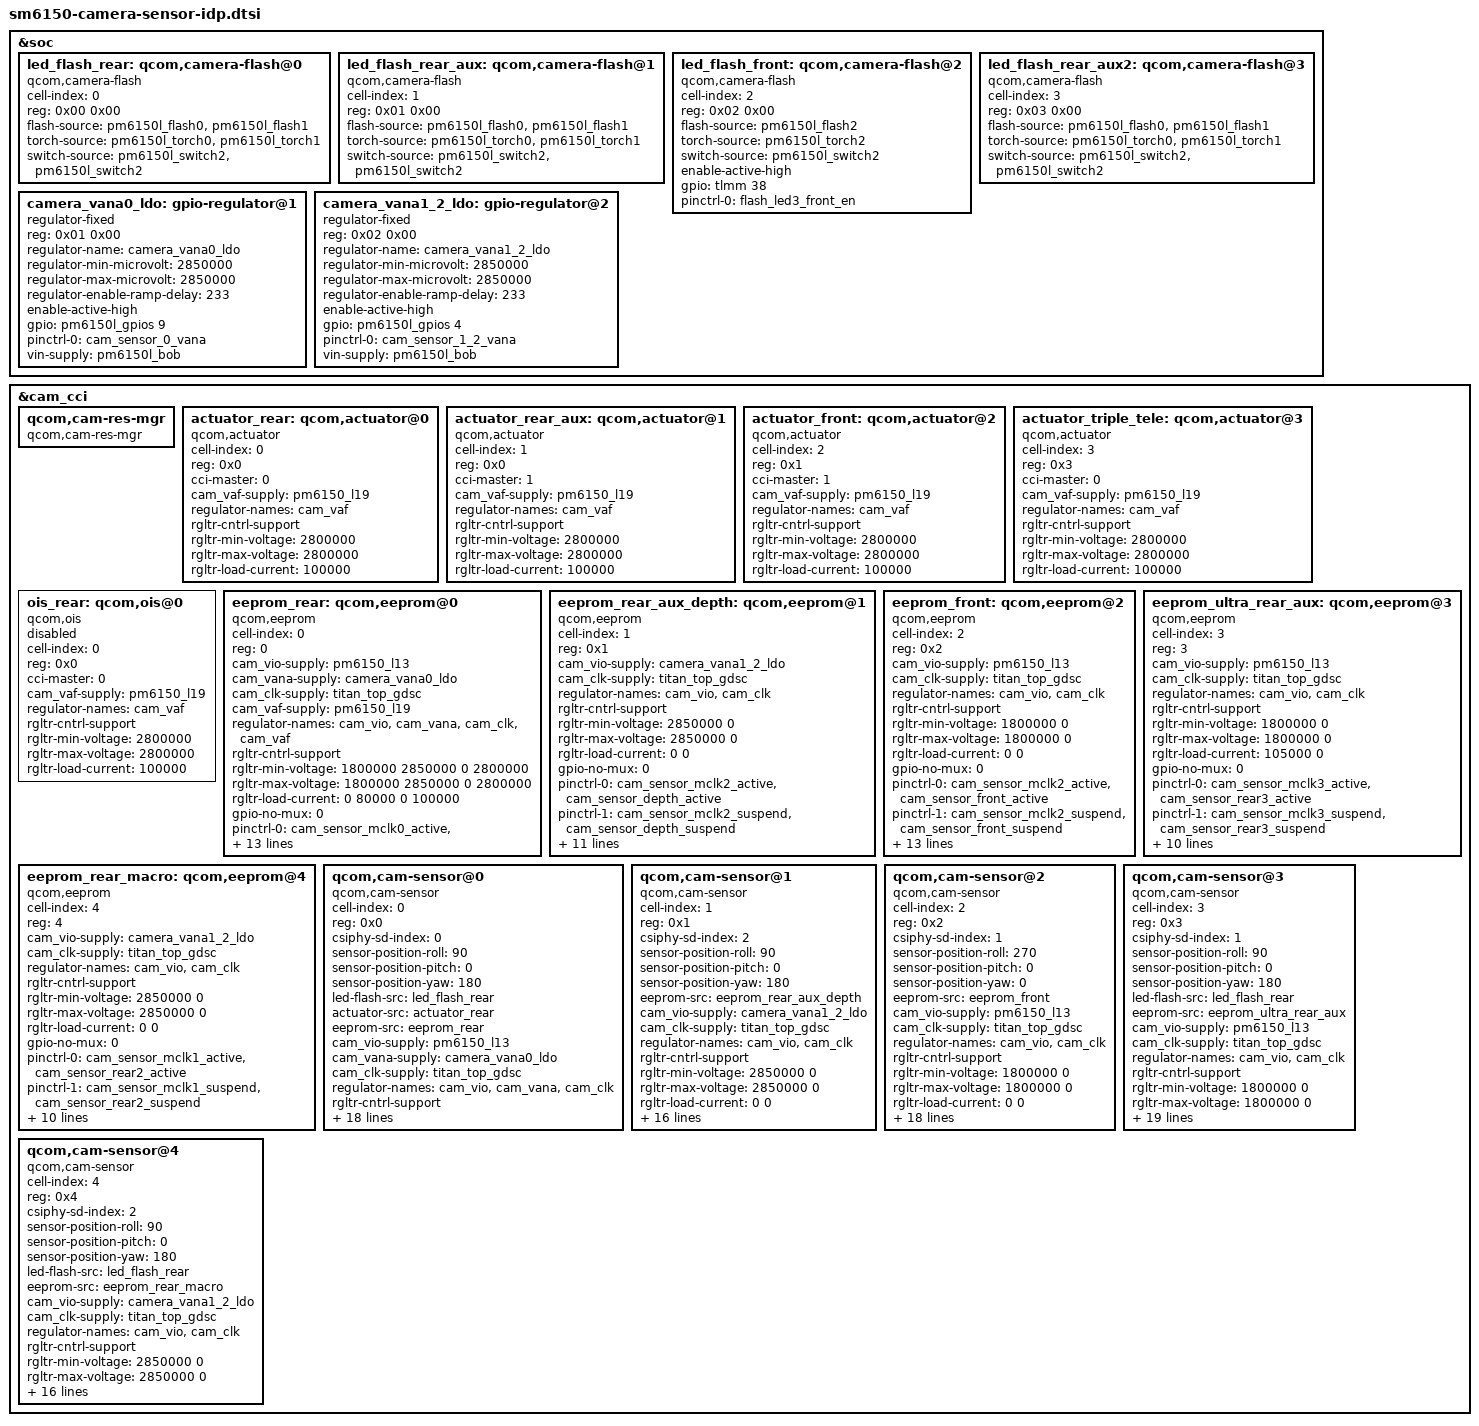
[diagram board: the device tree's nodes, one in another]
/*
 * Copyright (c) 2018-2019, The Linux Foundation. All rights reserved.
 * Copyright (C) 2021 XiaoMi, Inc.
 *
 * This program is free software; you can redistribute it and/or modify
 * it under the terms of the GNU General Public License version 2 and
 * only version 2 as published by the Free Software Foundation.
 *
 * This program is distributed in the hope that it will be useful,
 * but WITHOUT ANY WARRANTY; without even the implied warranty of
 * MERCHANTABILITY or FITNESS FOR A PARTICULAR PURPOSE.  See the
 * GNU General Public License for more details.
 */

&soc {

	led_flash_rear: qcom,camera-flash@0 {
		cell-index = <0>;
		reg = <0x00 0x00>;
		compatible = "qcom,camera-flash";
		flash-source = <&pm6150l_flash0 &pm6150l_flash1>;
		torch-source = <&pm6150l_torch0 &pm6150l_torch1>;
		switch-source = <&pm6150l_switch2 &pm6150l_switch2>;
		status = "ok";
	};

	led_flash_rear_aux: qcom,camera-flash@1 {
		cell-index = <1>;
		reg = <0x01 0x00>;
		compatible = "qcom,camera-flash";
		flash-source = <&pm6150l_flash0 &pm6150l_flash1>;
		torch-source = <&pm6150l_torch0 &pm6150l_torch1>;
		switch-source = <&pm6150l_switch2 &pm6150l_switch2>;
		status = "ok";
	};

	led_flash_front: qcom,camera-flash@2 {
		cell-index = <2>;
		reg = <0x02 0x00>;
		compatible = "qcom,camera-flash";
		flash-source = <&pm6150l_flash2>;
		torch-source = <&pm6150l_torch2>;
		switch-source = <&pm6150l_switch2>;
		status = "ok";
		enable-active-high;
		gpio = <&tlmm 38 0>;
		pinctrl-names = "default";
		pinctrl-0 = <&flash_led3_front_en>;
	};

	led_flash_rear_aux2: qcom,camera-flash@3 {
		cell-index = <3>;
		reg = <0x03 0x00>;
		compatible = "qcom,camera-flash";
		flash-source = <&pm6150l_flash0 &pm6150l_flash1>;
		torch-source = <&pm6150l_torch0 &pm6150l_torch1>;
		switch-source = <&pm6150l_switch2 &pm6150l_switch2>;
		status = "ok";
	};

	camera_vana0_ldo: gpio-regulator@1 {
		compatible = "regulator-fixed";
		reg = <0x01 0x00>;
		regulator-name = "camera_vana0_ldo";
		regulator-min-microvolt = <2850000>;
		regulator-max-microvolt = <2850000>;
		regulator-enable-ramp-delay = <233>;
		enable-active-high;
		gpio = <&pm6150l_gpios 9 0>;
		pinctrl-names = "default";
		pinctrl-0 = <&cam_sensor_0_vana>;
		vin-supply = <&pm6150l_bob>;
	};

	camera_vana1_2_ldo: gpio-regulator@2 {
		compatible = "regulator-fixed";
		reg = <0x02 0x00>;
		regulator-name = "camera_vana1_2_ldo";
		regulator-min-microvolt = <2850000>;
		regulator-max-microvolt = <2850000>;
		regulator-enable-ramp-delay = <233>;
		enable-active-high;
		gpio = <&pm6150l_gpios 4 0>;
		pinctrl-names = "default";
		pinctrl-0 = <&cam_sensor_1_2_vana>;
		vin-supply = <&pm6150l_bob>;
	};
};

&cam_cci {
	qcom,cam-res-mgr {
		compatible = "qcom,cam-res-mgr";
		status = "ok";
	};

	actuator_rear: qcom,actuator@0 {
		cell-index = <0>;
		reg = <0x0>;
		compatible = "qcom,actuator";
		cci-master = <0>;
		cam_vaf-supply = <&pm6150_l19>;
		regulator-names = "cam_vaf";
		rgltr-cntrl-support;
		rgltr-min-voltage = <2800000>;
		rgltr-max-voltage = <2800000>;
		rgltr-load-current = <100000>;
	};

	actuator_rear_aux: qcom,actuator@1 {
		cell-index = <1>;
		reg = <0x0>;
		compatible = "qcom,actuator";
		cci-master = <1>;
		cam_vaf-supply = <&pm6150_l19>;
		regulator-names = "cam_vaf";
		rgltr-cntrl-support;
		rgltr-min-voltage = <2800000>;
		rgltr-max-voltage = <2800000>;
		rgltr-load-current = <100000>;
	};

	actuator_front: qcom,actuator@2 {
		cell-index = <2>;
		reg = <0x1>;
		compatible = "qcom,actuator";
		cci-master = <1>;
		cam_vaf-supply = <&pm6150_l19>;
		regulator-names = "cam_vaf";
		rgltr-cntrl-support;
		rgltr-min-voltage = <2800000>;
		rgltr-max-voltage = <2800000>;
		rgltr-load-current = <100000>;
	};

	actuator_triple_tele: qcom,actuator@3 {
		cell-index = <3>;
		reg = <0x3>;
		compatible = "qcom,actuator";
		cci-master = <0>;
		cam_vaf-supply = <&pm6150_l19>;
		regulator-names = "cam_vaf";
		rgltr-cntrl-support;
		rgltr-min-voltage = <2800000>;
		rgltr-max-voltage = <2800000>;
		rgltr-load-current = <100000>;
	};

	ois_rear: qcom,ois@0 {
		cell-index = <0>;
		reg = <0x0>;
		compatible = "qcom,ois";
		cci-master = <0>;
		cam_vaf-supply = <&pm6150_l19>;
		regulator-names = "cam_vaf";
		rgltr-cntrl-support;
		rgltr-min-voltage = <2800000>;
		rgltr-max-voltage = <2800000>;
		rgltr-load-current = <100000>;
		status = "disabled";
	};

	eeprom_rear: qcom,eeprom@0 {
		cell-index = <0>;
		reg = <0>;
		compatible = "qcom,eeprom";
		cam_vio-supply = <&pm6150_l13>;
		cam_vana-supply = <&camera_vana0_ldo>;
		cam_clk-supply = <&titan_top_gdsc>;
		cam_vaf-supply = <&pm6150_l19>;
		regulator-names = "cam_vio", "cam_vana",
			"cam_clk", "cam_vaf";
		rgltr-cntrl-support;
		rgltr-min-voltage = <1800000 2850000 0 2800000>;
		rgltr-max-voltage = <1800000 2850000 0 2800000>;
		rgltr-load-current = <0 80000 0 100000>;
		gpio-no-mux = <0>;
		pinctrl-names = "cam_default", "cam_suspend";
		pinctrl-0 = <&cam_sensor_mclk0_active
				&cam_sensor_rear_active>;
		pinctrl-1 = <&cam_sensor_mclk0_suspend
				&cam_sensor_rear_suspend>;
		gpios = <&tlmm 28 0>,
			<&tlmm 47 0>;
		gpio-reset = <1>;
		gpio-req-tbl-num = <0 1>;
		gpio-req-tbl-flags = <1 0>;
		gpio-req-tbl-label = "CAMIF_MCLK0",
					"CAM_RESET0";
		sensor-mode = <0>;
		cci-master = <0>;
		status = "ok";
		clocks = <&clock_camcc CAM_CC_MCLK0_CLK>;
		clock-names = "cam_clk";
		clock-cntl-level = "turbo";
		clock-rates = <19200000>;
	};

	eeprom_rear_aux_depth: qcom,eeprom@1 {
		cell-index = <1>;
		reg = <0x1>;
		compatible = "qcom,eeprom";
		cam_vio-supply = <&camera_vana1_2_ldo>;
		cam_clk-supply = <&titan_top_gdsc>;
		regulator-names = "cam_vio",
			"cam_clk";
		rgltr-cntrl-support;
		rgltr-min-voltage = <2850000 0>;
		rgltr-max-voltage = <2850000 0>;
		rgltr-load-current = <0 0>;
		gpio-no-mux = <0>;
		pinctrl-names = "cam_default", "cam_suspend";
		pinctrl-0 = <&cam_sensor_mclk2_active
				&cam_sensor_depth_active>;
		pinctrl-1 = <&cam_sensor_mclk2_suspend
				&cam_sensor_depth_suspend>;
		gpios = <&tlmm 30 0>,
			<&tlmm 37 0>;
		gpio-reset = <1>;
		gpio-req-tbl-num = <0 1>;
		gpio-req-tbl-flags = <1 0>;
		gpio-req-tbl-label = "CAMIF_MCLK2",
					"CAM_RESET_DEPTH";
		sensor-mode = <0>;
		cci-master = <1>;
		status = "ok";
		clocks = <&clock_camcc CAM_CC_MCLK2_CLK>;
		clock-names = "cam_clk";
		clock-cntl-level = "turbo";
		clock-rates = <19200000>;
	};

	eeprom_front: qcom,eeprom@2 {
		cell-index = <2>;
		reg = <0x2>;
		compatible = "qcom,eeprom";
		cam_vio-supply = <&pm6150_l13>;
		//cam_vdig-supply = <&camera_dvdd_ldo>;//dvdd
		cam_clk-supply = <&titan_top_gdsc>;
		regulator-names = "cam_vio", //"cam_vana",
			"cam_clk";
		rgltr-cntrl-support;
		rgltr-min-voltage = <1800000 0>;
		rgltr-max-voltage = <1800000 0>;
		rgltr-load-current = <0 0>;
		gpio-no-mux = <0>;
		pinctrl-names = "cam_default", "cam_suspend";
		pinctrl-0 = <&cam_sensor_mclk2_active
				&cam_sensor_front_active>;
		pinctrl-1 = <&cam_sensor_mclk2_suspend
				&cam_sensor_front_suspend>;
		gpios = <&tlmm 30 0>,
			<&tlmm 38 0>,
		<&tlmm 94 0>,
		<&tlmm 121 0>;
		gpio-reset = <1>;
		gpio-custom1 = <2>;
		gpio-custom2 = <3>;
		gpio-req-tbl-num = <0 1 2 3>;
		gpio-req-tbl-flags = <1 0 0 0>;
		gpio-req-tbl-label = "CAMIF_MCLK2",
					"CAM2_RST_N",
		"CAM_SEL1_8V",
		"CAM_OE_LOW";
		sensor-mode = <0>;
		cci-master = <1>;
		status = "ok";
		clocks = <&clock_camcc CAM_CC_MCLK2_CLK>;
		clock-names = "cam_clk";
		clock-cntl-level = "turbo";
		clock-rates = <19200000>;
	};

	eeprom_ultra_rear_aux: qcom,eeprom@3 {
		cell-index = <3>;
		reg = <3>;
		compatible = "qcom,eeprom";
		cam_vio-supply = <&pm6150_l13>;
		//cam_vana-supply = <&camera_vana0_ldo>;
		cam_clk-supply = <&titan_top_gdsc>;
		regulator-names = "cam_vio",
			"cam_clk";
		rgltr-cntrl-support;
		rgltr-min-voltage = <1800000 0>;
		rgltr-max-voltage = <1800000 0>;
		rgltr-load-current = <105000 0>;
		gpio-no-mux = <0>;
		pinctrl-names = "cam_default", "cam_suspend";
		pinctrl-0 = <&cam_sensor_mclk3_active
				&cam_sensor_rear3_active>;
		pinctrl-1 = <&cam_sensor_mclk3_suspend
				&cam_sensor_rear3_suspend>;
		gpios = <&tlmm 31 0>,
			<&tlmm 40 0>;
		gpio-reset = <1>;
		gpio-req-tbl-num = <0 1>;
		gpio-req-tbl-flags = <1 0>;
		gpio-req-tbl-label = "CAMIF_MCLK3",
					"CAM_RESET3";
		sensor-mode = <0>;
		cci-master = <1>;
		status = "ok";
		clocks = <&clock_camcc CAM_CC_MCLK3_CLK>;
		clock-names = "cam_clk";
		clock-cntl-level = "turbo";
		clock-rates = <19200000>;
	};

	eeprom_rear_macro: qcom,eeprom@4 {
		cell-index = <4>;
		reg = <4>;
		compatible = "qcom,eeprom";
		cam_vio-supply = <&camera_vana1_2_ldo>;
		cam_clk-supply = <&titan_top_gdsc>;
		regulator-names = "cam_vio",
			"cam_clk";
		rgltr-cntrl-support;
		rgltr-min-voltage = <2850000 0>;
		rgltr-max-voltage = <2850000 0>;
		rgltr-load-current = <0 0>;
		gpio-no-mux = <0>;
		pinctrl-names = "cam_default", "cam_suspend";
		pinctrl-0 = <&cam_sensor_mclk1_active
				&cam_sensor_rear2_active>;
		pinctrl-1 = <&cam_sensor_mclk1_suspend
				&cam_sensor_rear2_suspend>;
		gpios = <&tlmm 29 0>,
			<&tlmm 45 0>;
		gpio-reset = <1>;
		gpio-req-tbl-num = <0 1>;
		gpio-req-tbl-flags = <1 0>;
		gpio-req-tbl-label = "CAMIF_MCLK1",
					"CAM_RESET2";
		sensor-mode = <0>;
		cci-master = <0>;
		status = "ok";
		clocks = <&clock_camcc CAM_CC_MCLK1_CLK>;
		clock-names = "cam_clk";
		clock-cntl-level = "turbo";
		clock-rates = <19200000>;
	};

	qcom,cam-sensor@0 {
		cell-index = <0>;
		compatible = "qcom,cam-sensor";
		reg = <0x0>;
		csiphy-sd-index = <0>;
		sensor-position-roll = <90>;
		sensor-position-pitch = <0>;
		sensor-position-yaw = <180>;
		led-flash-src = <&led_flash_rear>;
		actuator-src = <&actuator_rear>;
		//ois-src = <&ois_rear>;
		eeprom-src = <&eeprom_rear>;
		cam_vio-supply = <&pm6150_l13>;
		cam_vana-supply = <&camera_vana0_ldo>;
		cam_clk-supply = <&titan_top_gdsc>;
		regulator-names = "cam_vio", "cam_vana",
			"cam_clk";
		rgltr-cntrl-support;
		rgltr-min-voltage = <1800000 2850000 0>;
		rgltr-max-voltage = <1800000 2850000 0>;
		rgltr-load-current = <0 80000 0>;
		gpio-no-mux = <0>;
		pinctrl-names = "cam_default", "cam_suspend";
		pinctrl-0 = <&cam_sensor_mclk0_active
				&cam_sensor_rear_active>;
		pinctrl-1 = <&cam_sensor_mclk0_suspend
				&cam_sensor_rear_suspend>;
		gpios = <&tlmm 28 0>,
			<&tlmm 47 0>;
		gpio-reset = <1>;
		gpio-req-tbl-num = <0 1>;
		gpio-req-tbl-flags = <1 0>;
		gpio-req-tbl-label = "CAMIF_MCLK0",
					"CAM_RESET0";
		sensor-mode = <0>;
		cci-master = <0>;
		status = "ok";
		clocks = <&clock_camcc CAM_CC_MCLK0_CLK>;
		clock-names = "cam_clk";
		clock-cntl-level = "turbo";
		clock-rates = <19200000>;
	};

	qcom,cam-sensor@1 {
		cell-index = <1>;
		compatible = "qcom,cam-sensor";
		reg = <0x1>;
		csiphy-sd-index = <2>;
		sensor-position-roll = <90>;
		sensor-position-pitch = <0>;
		sensor-position-yaw = <180>;
//		led-flash-src = <&led_flash_rear_aux>;
//		actuator-src = <&actuator_rear_aux>;
		eeprom-src = <&eeprom_rear_aux_depth>;
		cam_vio-supply = <&camera_vana1_2_ldo>;
//		cam_vana-supply = <&camera_vana1_2_ldo>;
		cam_clk-supply = <&titan_top_gdsc>;
		regulator-names = "cam_vio",
			"cam_clk";
		rgltr-cntrl-support;
		rgltr-min-voltage = <2850000 0>;
		rgltr-max-voltage = <2850000 0>;
		rgltr-load-current = <0 0>;
		gpio-no-mux = <0>;
		pinctrl-names = "cam_default", "cam_suspend";
		pinctrl-0 = <&cam_sensor_mclk2_active
				&cam_sensor_depth_active>;
		pinctrl-1 = <&cam_sensor_mclk2_suspend
				&cam_sensor_depth_suspend>;
		gpios = <&tlmm 30 0>,
			<&tlmm 37 0>;
		gpio-reset = <1>;
		gpio-req-tbl-num = <0 1>;
		gpio-req-tbl-flags = <1 0>;
		gpio-req-tbl-label = "CAMIF_MCLK2",
					"CAM_RESET_DEPTH";
		sensor-mode = <0>;
		cci-master = <1>;
		status = "ok";
		clocks = <&clock_camcc CAM_CC_MCLK2_CLK>;
		clock-names = "cam_clk";
		clock-cntl-level = "turbo";
		clock-rates = <19200000>;
	};

	qcom,cam-sensor@2 {
		cell-index = <2>;
		compatible = "qcom,cam-sensor";
		reg = <0x2>;
		csiphy-sd-index = <1>;
		sensor-position-roll = <270>;
		sensor-position-pitch = <0>;
		sensor-position-yaw = <0>;
		eeprom-src = <&eeprom_front>;//eeprom
		cam_vio-supply = <&pm6150_l13>;
		//cam_vdig-supply = <&camera_dvdd_ldo>;//dvdd
		cam_clk-supply = <&titan_top_gdsc>;
		regulator-names = "cam_vio", //"cam_vana",
			"cam_clk";
		rgltr-cntrl-support;
		rgltr-min-voltage = <1800000 0>;
		rgltr-max-voltage = <1800000 0>;
		rgltr-load-current = <0 0>;
		gpio-no-mux = <0>;
		pinctrl-names = "cam_default", "cam_suspend";
		pinctrl-0 = <&cam_sensor_mclk2_active
				&cam_sensor_front_active>;
		pinctrl-1 = <&cam_sensor_mclk2_suspend
				&cam_sensor_front_suspend>;
		gpios = <&tlmm 30 0>,
			<&tlmm 38 0>,
		<&tlmm 94 0>,
		<&tlmm 121 0>;
		gpio-reset = <1>;
		gpio-custom1 = <2>;
		gpio-custom2 = <3>;
		gpio-req-tbl-num = <0 1 2 3>;
		gpio-req-tbl-flags = <1 0 0 0>;
		gpio-req-tbl-label = "CAMIF_MCLK2",
					"CAM2_RST_N",
		"CAM_SEL1_8V",
		"CAM_OE_LOW";
		sensor-mode = <0>;
		cci-master = <1>;
		status = "ok";
		clocks = <&clock_camcc CAM_CC_MCLK2_CLK>;
		clock-names = "cam_clk";
		clock-cntl-level = "turbo";
		clock-rates = <19200000>;
	};

	qcom,cam-sensor@3 {
		cell-index = <3>;
		compatible = "qcom,cam-sensor";
		reg = <0x3>;
		csiphy-sd-index = <1>;
		sensor-position-roll = <90>;
		sensor-position-pitch = <0>;
		sensor-position-yaw = <180>;
		led-flash-src = <&led_flash_rear>;
		//actuator-src = <&actuator_rear_aux>;
		eeprom-src = <&eeprom_ultra_rear_aux>;
		cam_vio-supply = <&pm6150_l13>;
		//cam_vana-supply = <&camera_vana0_ldo>;
		cam_clk-supply = <&titan_top_gdsc>;
		regulator-names = "cam_vio",
			"cam_clk";
		rgltr-cntrl-support;
		rgltr-min-voltage = <1800000 0>;
		rgltr-max-voltage = <1800000 0>;
		rgltr-load-current = <105000 0>;
		gpio-no-mux = <0>;
		pinctrl-names = "cam_default", "cam_suspend";
		pinctrl-0 = <&cam_sensor_mclk3_active
				&cam_sensor_rear3_active>;
		pinctrl-1 = <&cam_sensor_mclk3_suspend
				&cam_sensor_rear3_suspend>;
		gpios = <&tlmm 31 0>,
			<&tlmm 40 0>,
			<&tlmm 94 0>,
			<&tlmm 121 0>;
		gpio-reset = <1>;
		gpio-custom1 = <2>;
		gpio-custom2 = <3>;
		gpio-req-tbl-num = <0 1 2 3>;
		gpio-req-tbl-flags = <1 0 0 0>;
		gpio-req-tbl-label = "CAMIF_MCLK3",
					"CAM_RESET3",
					"CAM_SEL",
					"CAM_OE";
		sensor-mode = <0>;
		cci-master = <1>;
		status = "ok";
		clocks = <&clock_camcc CAM_CC_MCLK3_CLK>;
		clock-names = "cam_clk";
		clock-cntl-level = "turbo";
		clock-rates = <19200000>;
	};

	qcom,cam-sensor@4 {
		cell-index = <4>;
		compatible = "qcom,cam-sensor";
		reg = <0x4>;
		csiphy-sd-index = <2>;
		sensor-position-roll = <90>;
		sensor-position-pitch = <0>;
		sensor-position-yaw = <180>;
		led-flash-src = <&led_flash_rear>;
		eeprom-src = <&eeprom_rear_macro>;
		cam_vio-supply = <&camera_vana1_2_ldo>;
		cam_clk-supply = <&titan_top_gdsc>;
		regulator-names = "cam_vio",
			"cam_clk";
		rgltr-cntrl-support;
		rgltr-min-voltage = <2850000 0>;
		rgltr-max-voltage = <2850000 0>;
		rgltr-load-current = <0 0>;
		gpio-no-mux = <0>;
		pinctrl-names = "cam_default", "cam_suspend";
		pinctrl-0 = <&cam_sensor_mclk1_active
				&cam_sensor_rear2_active>;
		pinctrl-1 = <&cam_sensor_mclk1_suspend
				&cam_sensor_rear2_suspend>;
		gpios = <&tlmm 29 0>,
			<&tlmm 45 0>;
		gpio-reset = <1>;
		gpio-req-tbl-num = <0 1>;
		gpio-req-tbl-flags = <1 0>;
		gpio-req-tbl-label = "CAMIF_MCLK1",
					"CAM_RESET2";
		sensor-mode = <0>;
		cci-master = <0>;
		status = "ok";
		clocks = <&clock_camcc CAM_CC_MCLK1_CLK>;
		clock-names = "cam_clk";
		clock-cntl-level = "turbo";
		clock-rates = <19200000>;
	};
};
